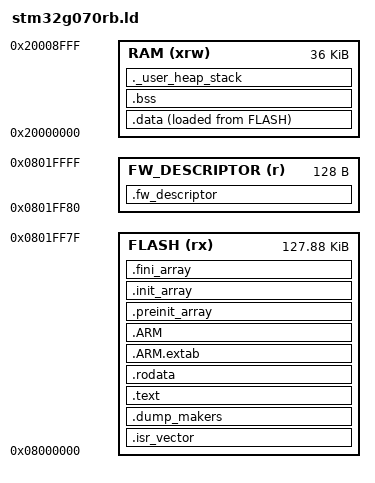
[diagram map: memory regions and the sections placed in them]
/**
 ******************************************************************************
 * @file      LinkerScript.ld
 * @author    Auto-generated by STM32CubeIDE
 * @brief     Linker script for STM32G070RBTx Device from STM32G0 series
 *                      128Kbytes FLASH
 *                      36Kbytes RAM
 *
 *            Set heap size, stack size and stack location according
 *            to application requirements.
 *
 *            Set memory bank area and size if external memory is used
 ******************************************************************************
 * @attention
 *
 * Copyright (c) 2020 STMicroelectronics.
 * All rights reserved.
 *
 * This software is licensed under terms that can be found in the LICENSE file
 * in the root directory of this software component.
 * If no LICENSE file comes with this software, it is provided AS-IS.
 *
 ******************************************************************************
 */

/* Entry Point */
ENTRY(Reset_Handler)

/* Highest address of the user mode stack */
_estack = ORIGIN(RAM) + LENGTH(RAM);  /* end of "RAM" Ram type memory */

_Min_Heap_Size = 0x200;  /* required amount of heap  */
_Min_Stack_Size = 0x400;  /* required amount of stack */

TOTAL_FLASH_SIZE = 128K;
FLASH_ONE_PAGE = 2K;
FW_ORIGIN = 0x8000000;

DESCRIPTOR_SIZE = 128; /* 40B was needed when this section was first created -> x2 + round => 128B */
APP_SIZE = TOTAL_FLASH_SIZE - DESCRIPTOR_SIZE;

/* Memories definition */
MEMORY
{
  RAM (xrw)             : ORIGIN = 0x20000000,                                      LENGTH = 36K
  FLASH (rx)            : ORIGIN = FW_ORIGIN,                                       LENGTH = APP_SIZE
  FW_DESCRIPTOR (r)     : ORIGIN = FW_ORIGIN + TOTAL_FLASH_SIZE - DESCRIPTOR_SIZE,  LENGTH = DESCRIPTOR_SIZE
}

/* Sections */
SECTIONS
{
  /* The startup code into "FLASH" Rom type memory */
  .isr_vector :
  {
    __isr_vector = .;
    . = ALIGN(4);
    KEEP(*(.isr_vector)) /* Startup code */
    . = ALIGN(4);
  } >FLASH

  /* this section is required so that all functions involved in crash dumping are in a 'safe region'
   * and will not be overwritten by the dump itself */
  .dump_makers : {
    . = ALIGN(4);
    *(.text.Default_Handler) /* keep Default_Handler close to HardFault_Handler */
    *CrashCatcher_armv6m* (.text) /* guarantee that HardFault_Handler is close to Default_Handler */
    *CrashCatcher* (.text .text* .rodata .rodata*) /* CrashCatcher stuff */
    *crash_catcher* (.text .text* .rodata .rodata*) /* CrashCatcher stuff */
    *hal* (.text .text* .rodata .rodata*) /* HAL stuff */
    *tim* (.text .text* .rodata .rodata*) /* timing stuff */
    *lib* (.text .text* .rodata .rodata*) /* arm gcc stuff */
    *freertos_openocd*  (.text .text* .rodata .rodata*) /* debugger stuff - needed only for debugging */
    *(.text)           /* .text sections (code) - mostly arm gcc stuff */
    . = ALIGN(4);
    __dump_makers_end = ALIGN(FLASH_ONE_PAGE);
  } >FLASH

  /* The program code and other data into "FLASH" Rom type memory */
  .text :
  {
    . = ALIGN(4);
    *(.text*)          /* .text* sections (code) */
    *(.glue_7)         /* glue arm to thumb code */
    *(.glue_7t)        /* glue thumb to arm code */
    *(.eh_frame)

    KEEP (*(.init))
    KEEP (*(.fini))

    . = ALIGN(4);
    _etext = .;        /* define a global symbols at end of code */
  } >FLASH

  /* Constant data into "FLASH" Rom type memory */
  .rodata :
  {
    . = ALIGN(4);
    *(.rodata)         /* .rodata sections (constants, strings, etc.) */
    *(.rodata*)        /* .rodata* sections (constants, strings, etc.) */
    . = ALIGN(4);
  } >FLASH

  .ARM.extab   : {
    . = ALIGN(4);
    *(.ARM.extab* .gnu.linkonce.armextab.*)
    . = ALIGN(4);
  } >FLASH

  .ARM : {
    . = ALIGN(4);
    __exidx_start = .;
    *(.ARM.exidx*)
    __exidx_end = .;
    . = ALIGN(4);
  } >FLASH

  .preinit_array     :
  {
    . = ALIGN(4);
    PROVIDE_HIDDEN (__preinit_array_start = .);
    KEEP (*(.preinit_array*))
    PROVIDE_HIDDEN (__preinit_array_end = .);
    . = ALIGN(4);
  } >FLASH

  .init_array :
  {
    . = ALIGN(4);
    PROVIDE_HIDDEN (__init_array_start = .);
    KEEP (*(SORT(.init_array.*)))
    KEEP (*(.init_array*))
    PROVIDE_HIDDEN (__init_array_end = .);
    . = ALIGN(4);
  } >FLASH

  .fini_array :
  {
    . = ALIGN(4);
    PROVIDE_HIDDEN (__fini_array_start = .);
    KEEP (*(SORT(.fini_array.*)))
    KEEP (*(.fini_array*))
    PROVIDE_HIDDEN (__fini_array_end = .);
    . = ALIGN(4);
  } >FLASH

  /* Used by the startup to initialize data */
  _sidata = LOADADDR(.data);

  /* Initialized data sections into "RAM" Ram type memory */
  .data :
  {
    . = ALIGN(4);
    _sdata = .;        /* create a global symbol at data start */

    PROVIDE_HIDDEN (__start_log_components = .);
    KEEP(*(.data.log_components))
    PROVIDE_HIDDEN (__end_log_components = .);

    PROVIDE_HIDDEN (__start_metric_definitions = .);
    KEEP(*(.data.metric_definitions))
    PROVIDE_HIDDEN (__end_metric_definitions = .);

    *(.data)           /* .data sections */
    *(.data*)          /* .data* sections */

    . = ALIGN(4);
    _edata = .;        /* define a global symbol at data end */

  } >RAM AT> FLASH

  /* Uninitialized data section into "RAM" Ram type memory */
  . = ALIGN(4);
  .bss :
  {
    /* This is used by the startup in order to initialize the .bss section */
    _sbss = .;         /* define a global symbol at bss start */
    __bss_start__ = _sbss;
    *(.bss)
    *(.bss*)
    *(COMMON)

    . = ALIGN(4);
    _ebss = .;         /* define a global symbol at bss end */
    __bss_end__ = _ebss;
  } >RAM

  /* User_heap_stack section, used to check that there is enough "RAM" Ram  type memory left */
  ._user_heap_stack :
  {
    . = ALIGN(8);
    PROVIDE ( end = . );
    PROVIDE ( _end = . );
    . = . + _Min_Heap_Size;
    . = . + _Min_Stack_Size;
    . = ALIGN(8);
  } >RAM

  /* Remove information from the compiler libraries */
  /DISCARD/ :
  {
    libc.a:* ( * )
    libm.a:* ( * )
    libgcc.a:* ( * )
  }

  .fw_descriptor : {
    . = ALIGN(4);
    KEEP(*(*.fw_descriptor*));
  } >FW_DESCRIPTOR

  __fw_descriptor_start = ORIGIN(FW_DESCRIPTOR);
  __fw_descriptor_length = LENGTH(FW_DESCRIPTOR);
  __flash_start = ORIGIN(FLASH);

  .ARM.attributes 0 : { *(.ARM.attributes) }
}
